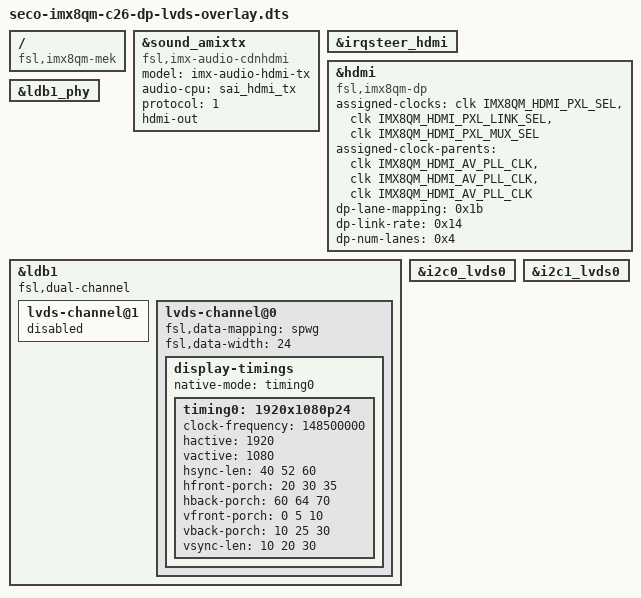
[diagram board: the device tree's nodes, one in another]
/*
 * Copyright 2017-2018 NXP
 *
 * This program is free software; you can redistribute it and/or
 * modify it under the terms of the GNU General Public License
 * as published by the Free Software Foundation; either version 2
 * of the License, or (at your option) any later version.
 *
 * This program is distributed in the hope that it will be useful,
 * but WITHOUT ANY WARRANTY; without even the implied warranty of
 * MERCHANTABILITY or FITNESS FOR A PARTICULAR PURPOSE.  See the
 * GNU General Public License for more details.
 */
/*
 * DP+LVDS  - Display Port and ldb1 display.
 */

/dts-v1/;
/plugin/;

#include <dt-bindings/clock/imx8qm-clock.h>

/ {
        compatible = "fsl,imx8qm-mek","fsl,seco-imx8qm-c26", "fsl,imx8qm";

/*  __________________________________________________________________________
 * |                                                                          |
 * |                                 DP OVERLAY                               |
 * |__________________________________________________________________________|
 */


        fragment@0 {
                target = <&sound_amixtx>;
                __overlay__ {
                                compatible = "fsl,imx-audio-cdnhdmi";
                                model = "imx-audio-hdmi-tx";
                                audio-cpu = <&sai_hdmi_tx>;
                                protocol = <1>;
                                hdmi-out;
                        };
        };

        fragment@1 {
                target = <&irqsteer_hdmi>;
                __overlay__ {
                        status = "okay";
                };
        };

        fragment@2 {
                target = <&hdmi>;
                __overlay__ {
			compatible = "fsl,imx8qm-dp";
                        assigned-clocks = <&clk IMX8QM_HDMI_PXL_SEL>,
                                                        <&clk IMX8QM_HDMI_PXL_LINK_SEL>,
                                                        <&clk IMX8QM_HDMI_PXL_MUX_SEL>;
                        assigned-clock-parents = <&clk IMX8QM_HDMI_AV_PLL_CLK>,
                                                        <&clk IMX8QM_HDMI_AV_PLL_CLK>,
                                                        <&clk IMX8QM_HDMI_AV_PLL_CLK>;

                        dp-lane-mapping = <0x1b>;
                        dp-link-rate = <0x14>;
                        dp-num-lanes = <0x4>;

                        status = "okay";
                };
        };

/*  __________________________________________________________________________
 * |                                                                          |
 * |                               LVDS1 OVERLAY                              |
 * |__________________________________________________________________________|
 */


	fragment@3 {
                target = <&ldb1_phy>;
                __overlay__ {
			status = "okay";
        	};
        };

	fragment@4 {
                target = <&ldb1>;
                __overlay__ {
                        status = "okay";
			fsl,dual-channel;

			lvds-channel@1 {
				status = "disabled";
		    	};
		    
			lvds-channel@0 {
				fsl,data-mapping = "spwg";
				fsl,data-width = <24>;
				status = "okay";
				display-timings {
					native-mode = <&timing0>;
			                timing0: 1920x1080p24 {
						/* 1920x1080p24 */
						clock-frequency = <148500000>;
						hactive = <1920>;
						vactive = <1080>;
						hsync-len = <40 52 60>;
						hfront-porch = <20 30 35>;
						hback-porch = <60 64 70>;
						vfront-porch = <0 5 10>;
						vback-porch = <10 25 30>;
						vsync-len = <10 20 30>;
					};
				};	
			};
                };
        };

	fragment@5 {
                target = <&i2c0_lvds0>;
                __overlay__ {
			status = "okay";
                };
        };

	fragment@6 {
                target = <&i2c1_lvds0>;
                __overlay__ {
                        status = "okay"; 
                };
        };
		
};
